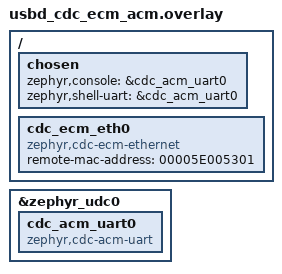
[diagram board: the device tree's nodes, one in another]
/*
 * CDC-ECM networking + CDC-ACM console
 */

/ {
	chosen {
		zephyr,console = &cdc_acm_uart0;
		zephyr,shell-uart = &cdc_acm_uart0;
	};

	cdc_ecm_eth0: cdc_ecm_eth0 {
		compatible = "zephyr,cdc-ecm-ethernet";
		remote-mac-address = "00005E005301";
	};
};

&zephyr_udc0 {
	cdc_acm_uart0: cdc_acm_uart0 {
		compatible = "zephyr,cdc-acm-uart";
	};
};
